# dm648_cslr_uart register map
Vendor: Texas Instruments
Peripheral module from a debugger description file.
Registers are 32-bit, access not given, reset 0x0 unless marked. A register's access mark holds for its fields unless they carry their own. Offsets are as the file gives them; lines under a group give offsets from that group; [hi:lo] are bit positions; {n}, {i} and the like mark numbered series; 'fields as' and 'values as' point back to an identical list; <NAME> marks a mode.

## UART
0x00 RBR — Receive Buffer Register
  [7:0] RBR ro — Receiver Buffer Register(Read Only)
0x00 THR — Transmitter Holding Register
  [7:0] THR wo — Transmitter Holding Register(Write Only)
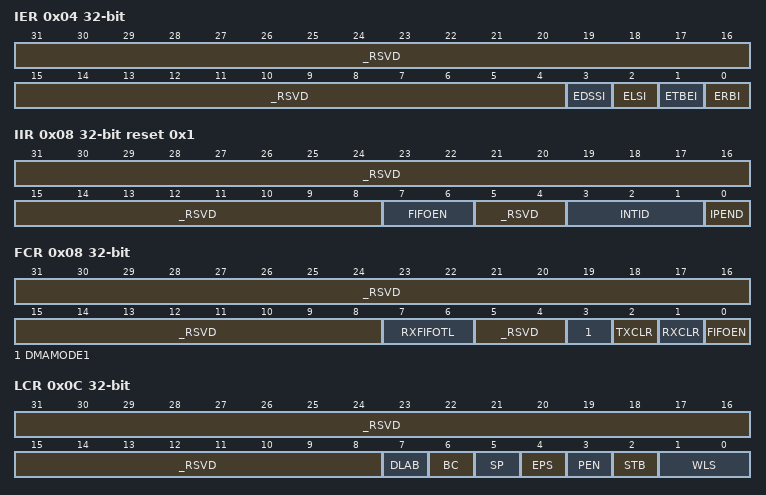
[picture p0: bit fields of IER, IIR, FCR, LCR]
0x04 IER — Interrupt Enable Register
  [31:4] _RSVD — These bits are not used (access N)
  [3] EDSSI rw — Enables the Modem Status Interrupt
    0=DISABLE (MSI Interrupt Disabled); 1=ENABLE (MSI Interrupt Enabled)
  [2] ELSI rw — Enables the receiver line status Interrupt
    0=DISABLE (RLSI Interrupt Disabled); 1=ENABLE (RLSI Interrupt Enabled)
  [1] ETBEI rw — Enables the THRE Interrupt
    0=DISABLE (THREI Interrupt Disabled); 1=ENABLE (THREI Interrupt Enabled)
  [0] ERBI rw — Enables the received data available interrupt and character time-out indication interrupt
    0=DISABLE (Receiver Data Availabe Interrupt Disabled); 1=ENABLE (Receiver Data Availabe Interrupt Enabled)
0x08 IIR reset 0x1 — Interrupt Identification Register (Read-only register)
  [31:8] _RSVD — These bits are not used (access N)
  [7:6] FIFOEN ro — Always cleared in non-FIFO Mode.They are set when bit 0 of FIFO control register is set(FCR[0])
  [5:4] _RSVD — These bits are not used(always cleared) (access N)
  [3:1] INTID ro — Encodes different types of interrupts
    0=MODSTAT; 1=THRE; 2=RDA; 3=RLS; 6=CTI
  [0] IPEND ro — Used either in a hardwire prioritized(nirq) or polled interrupt system. 0->An interrupt is pending.
0x08 FCR — FIFO Control Register (Write-only register)
  [31:8] _RSVD — These bits are not used (access N)
  [7:6] RXFIFOTL wo — Sets the trigger level of the receiver FIFO
  [5:4] _RSVD — These bits are not used (access N)
  [3] DMAMODE1 wo — When FCR[0] is set, setting this bit will select mode 1 for the DMA
    0=DISABLE (Disable DMA Mode); 1=ENABLE (Enable DMA Mode)
  [2] TXCLR wo — Setting this bit clears the transmitter FIFO and resets the transmitter FIFO counter.
    0=NOACTION; 1=XMIT_FIFO_CLEARE (Clears the Trasmitter FIFO)
  [1] RXCLR wo — Setting this bit clears the receiver FIFO counter. The shift register is not cleared.
    1=RECV_FIFO_CNT_CLEARE (Clears the Receiver FIFO Counter)
  [0] FIFOEN wo — Enables the transmitter and receiver FIFOs
    0=DISABLE (Disable FIFO Mode); 1=ENABLE (Enable FIFO Mode)
0x0C LCR — Line Control Register
  [31:8] _RSVD — These bits are not used (access N)
  [7] DLAB rw — This bit is the divisor latch access bit
    0=DISABLE (Access the RBR/THR and IER); 1=ENABLE (Access the divisor latches)
  [6] BC rw — This bit is the break control bit.
    0=DISABLE (Break Control function is disabled); 1=ENABLE (Break Control function is enabled)
  [5] SP rw — When this bit is set: if even parity is selected, the parity bit is transmitted and checked as cleared. If odd parity is selected, the parity bit is transmitted and checked as set.
    0=DISABLE; 1=ENABLE
  [4] EPS rw — This bit is the even parity bit
    0=ODD_PARITY (Odd parity selection); 1=EVEN_PARITY (Even Parity Selection)
  [3] PEN rw — This bit is the parity enable bit
    0=DISABLE (Parity selection disabled); 1=ENABLE (Parity selection enabled)
  [2] STB rw — This bit specifies either one, one and a half, or two stop bits in each transmitted
    0=1STOPBIT; 1=2R1.5STOPBITS (2 or 1.5 stop bits depending on WLS selection)
  [1:0] WLS rw — These two bits specify the number of bits in each transmitted or received serial
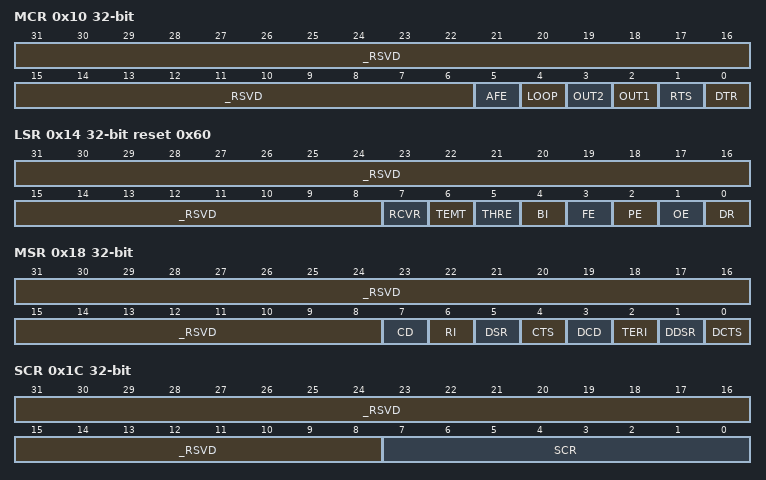
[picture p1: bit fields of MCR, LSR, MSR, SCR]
0x10 MCR — Modem Control Register
  [31:6] _RSVD — These bits are not used (access N)
  [5] AFE rw — Autoflow control enable bit. When AFE='1', the autoflow control is enabled.
    1=ENABLE; 0=DISABLE
  [4] LOOP rw — Loop Mode Bit. When LOOP='1', Internal Loop Mode enabled. When='0', loop back is disabled
    1=ENABLE; 0=DISABLE
  [3] OUT2 rw — OUT2 Control bit
    1=ENABLE; 0=DISABLE
  [2] OUT1 rw — OUT1 Control bit
    1=ENABLE; 0=DISABLE
  [1] RTS rw — RTS Control bit
    1=ENABLE; 0=DISABLE
  [0] DTR rw — DTR Control bit
    1=ENABLE; 0=DISABLE
0x14 LSR reset 0x60 — Line Status Register
  [31:8] _RSVD — These bits are not used (access N)
  [7] RCVR ro — In the non-FIFO mode, this bit is set when there is a parity error, framing error, or break indicator in the receiver buffer register (RBR). It is cleared when the CPU reads the erroneous data. In the FIFO mode, this bit is set when there is at least one parity error, framing error, or break indicator in the FIFO.
  [6] TEMT ro — This is the transmitter empty (TEMT) indicator bit. This bit is set when both the THR and the TSR are empty. It is cleared when either the THR or the TSR contains a data character. In the FIFO mode, this bit is set when both the transmitter FIFO and the shift register are empty.
  [5] THRE ro — This is the transmitter holding register empty (THRE) indicator bit. This bit is set whenever the THR is empty. This bit is cleared at the same time when the CPU loads the THR. In the FIFO mode, this bit is set when the transmitter FIFO is empty, and it is cleared when at least one byte is loaded into the FIFO.
  [4] BI ro — This is the break indicator (BI) bit. This bit is set whenever the receive data input was held low for longer than a full-word transmission time. This bit is cleared after the CPU reads the erroneous data.
  [3] FE ro — This is the frame error (FE) bit. This bit is set whenever the receive data character does not have a valid stop bit. This bit is cleared after the CPU reads the erroneous data.
  [2] PE ro — This is the parity error (PE) bit. This bit is set whenever the parity of the receive data character does not match the parity selected in the LCR[4]. This bit is cleared after the CPU reads the erroneous data.
  [1] OE ro — This is the overrun error (OE) bit. This bit is set whenever a character is written to the RBR before the previous character was read by the CPU. This bit is cleared every time the CPU reads the contents of the LSR.
  [0] DR ro — This is the data ready (DR) bit. 1: Complete incoming character received and transferred into RBR/FIFO 0: All the data read from RBR/FIFO
0x18 MSR — Modem Status Register
  [31:8] _RSVD — These bits are not used. (access N)
  [7] CD ro — This bit is the complement of the DCD input.
    1=CD; 0=NOCD
  [6] RI ro — This bit is the complement of the RI input.
    1=RI; 0=NORI
  [5] DSR ro — This bit is the complement of the DSR input.
    1=DSR; 0=NODSR
  [4] CTS ro — This bit is the complement of the CTS input.
    1=CTS; 0=NOCTS
  [3] DCD ro — This is the change in DCD (DCD) indicator bit.
    1=DCD (When DCD is set and the modem status interrupt is enabled, a modem status interrupt is generated.); 0=NODCD
  [2] TERI ro — This is the trailing edge of RI (TERI) indicator bit.
    1=TERI (When TERI is set and the modem status interrupt is enabled, a modem status interrupt is generated.); 0=NOTERI
  [1] DDSR ro — This is the change in DSR (DDSR) indicator bit.
    1=DDSR (When DDSR is set and the modem status interrupt is enabled, a modem status interrupt is generated.); 0=NODDSR
  [0] DCTS ro — This is the change in CTS (DCTS) indicator bit.
    1=DCTS (When DCTS is set (autoflow control is not enabled and the modem status interrupt is enabled), a modem status interrupt is generated.); 0=NODCTS
0x1C SCR — Scratch Register
  [31:8] _RSVD — These bits are not used. (access N)
  [7:0] SCR rw — Used as programmer's scartch pad, temporarily hold programmer's data.
0x20 DLL 8-bit rw — Divisior Latch(LSB)
  [7:0] DLL — Stores the LSB of 16-bit divisor for generation of the baud clock in the baud rate generator.
0x24 DLH 8-bit rw — Divisior Latch(MSB)
  [7:0] DLH — Stores the MSB of 16-bit divisor for generation of the baud clock in the baud rate generator.
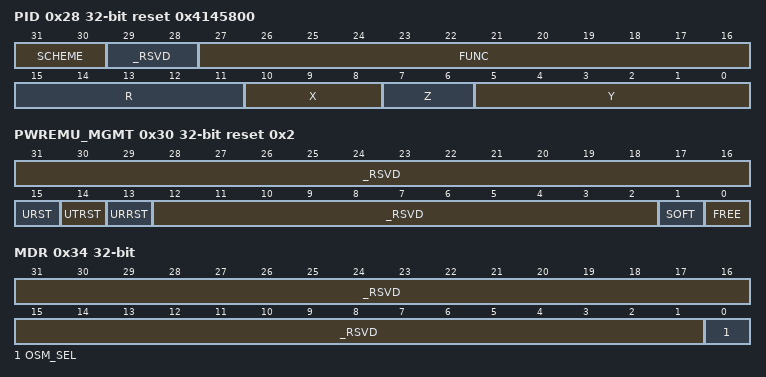
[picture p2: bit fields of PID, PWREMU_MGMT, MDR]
0x28 PID reset 0x4145800 (reset mask 0xFFFF800) — Peripheral ID Register
  [31:30] SCHEME ro — UART follows the new PID scheme. This value should be 0b01
  [29:28] _RSVD — These bits are not used. (access N)
  [27:16] FUNC ro — UART's assigned FUNC value is 0x414
  [15:11] R ro — Defined by design team and matches PDS release to chip teams
  [10:8] X ro — UART major spec release is set to 0b001
  [7:6] Z ro — Defined by design team and is set to 0 for major RTL releases
  [5:0] Y ro — UART minor specrelease is set to 0b000010
0x2C PID_TYP — Peripheral ID Register TYPE
  [31:0] _RSVD — These bits are not used. (access N)
0x30 PWREMU_MGMT reset 0x2 — Power Management and Emulation Register
  [31:16] _RSVD — These bits are not used. (access N)
  [15] URST rw — This bit resets and enables both the receiver and transmitter.
    1=TXRXENABLE (The receiver and transmitter are enabled.); 0=TXRXDISABLE (The receiver and transmitter are disabled and in reset state.)
  [14] UTRST rw — This bit resets and enables the transmitter.
    1=TXENABLE (The transmitter is enabled.); 0=TXDISABLE (The transmitter is disabled and in reset state.)
  [13] URRST rw — This bit resets and enables the receiver.
    1=RXENABLE (The receiver is enabled.); 0=RXDISABLE (The receiver is disabled and in reset state.)
  [12:2] _RSVD — These bits are not used. (access N)
  [1] SOFT rw — Always reads one and write does not have any affect
  [0] FREE rw — This bit determines emulation mode functionality of the UART.
    1=UARTRUN (UART runs free.); 0=UARTSTOP (UART stops immediately.)
0x34 MDR — Mode Definition Register
  [31:1] _RSVD — These bits are not used. (access N)
  [0] OSM_SEL rw — This bit determines over-sampling mode.
